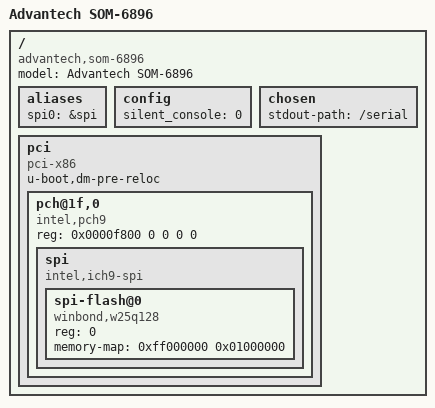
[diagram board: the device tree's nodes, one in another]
/dts-v1/;

/include/ "skeleton.dtsi"
/include/ "serial.dtsi"
/include/ "rtc.dtsi"
/include/ "tsc_timer.dtsi"
/include/ "coreboot_fb.dtsi"

/ {
	model = "Advantech SOM-6896";
	compatible = "advantech,som-6896", "intel,broadwell";

	aliases {
		spi0 = &spi;
	};

	config {
	       silent_console = <0>;
	};

	chosen {
		stdout-path = "/serial";
	};

	pci {
		compatible = "pci-x86";
		#address-cells = <3>;
		#size-cells = <2>;
		u-boot,dm-pre-reloc;
		ranges = <0x02000000 0x0 0xe0000000 0xe0000000 0 0x10000000
			0x42000000 0x0 0xd0000000 0xd0000000 0 0x10000000
			0x01000000 0x0 0x2000 0x2000 0 0xe000>;

		pch@1f,0 {
			reg = <0x0000f800 0 0 0 0>;
			compatible = "intel,pch9";

			spi: spi {
				#address-cells = <1>;
				#size-cells = <0>;
				compatible = "intel,ich9-spi";
				spi-flash@0 {
					reg = <0>;
					compatible = "winbond,w25q128", "spi-flash";
					memory-map = <0xff000000 0x01000000>;
				};
			};
		};
	};

};
